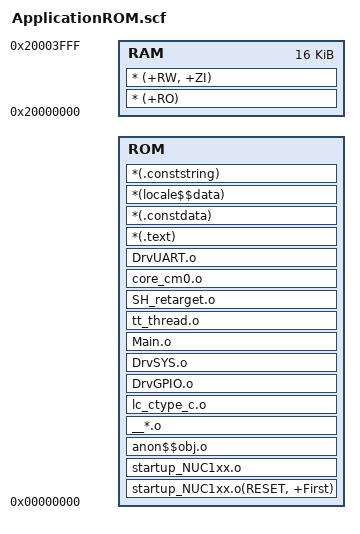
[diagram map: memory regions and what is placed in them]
ROM 0x00000000
{ 
	ROM 0x0
	{
        startup_NUC1xx.o(RESET, +First)
        startup_NUC1xx.o
        anon$$obj.o
        __*.o
        lc_ctype_c.o
        DrvGPIO.o
        DrvSYS.o
        Main.o
        tt_thread.o
        SH_retarget.o
        core_cm0.o
        DrvUART.o
        *(.text)
        *(.constdata)
        *(locale$$data)
        *(.conststring)
       
    }

	RAM 0x20000000 0x4000
	{
 		* (+RO)
		* (+RW, +ZI)
	}
}
